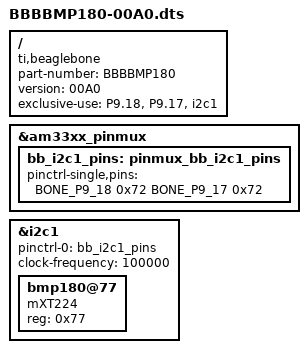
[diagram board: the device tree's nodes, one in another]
/*Custom Overlay for BMP180
 */
/dts-v1/;
/plugin/;

#include <dt-bindings/board/am335x-bbw-bbb-base.h>
#include <dt-bindings/pinctrl/am33xx.h>

/ {
	compatible = "ti,beaglebone", "ti,beaglebone-black", "ti,beaglebone-green";

	// identification
	part-number = "BBBBMP180";
	version = "00A0";

	// resources this cape uses
	exclusive-use =
		"P9.18",		// i2c1_sda
		"P9.17",		// i2c1_scl

		"i2c1";		// hardware ip used


	fragment@0 {
		target = <&am33xx_pinmux>;
		__overlay__ {
			bb_i2c1_pins: pinmux_bb_i2c1_pins {
				pinctrl-single,pins = <
					BONE_P9_18 0x72	// spi0_d1.i2c1_sda, SLEWCTRL_SLOW | INPUT_PULLUP | MODE2
					BONE_P9_17 0x72	// spi0_cs0.i2c1_scl, SLEWCTRL_SLOW | INPUT_PULLUP | MODE2
				>;
			};
		};
	};

	fragment@1 {
		target = <&i2c1>;	// i2c1 is numbered correctly
		__overlay__ {
			status = "okay";
			pinctrl-names = "default";
			pinctrl-0 = <&bb_i2c1_pins>;

			// configuration start
			clock-frequency = <100000>;

			#address-cells = <1>;
			#size-cells = <0>;

			bmp180@77 {
				compatible = "mXT224";
				reg = <0x77>;
			};
		};
	};
};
